# RL7005_IP_SVD register map
Vendor: Realtek
Registers are 32-bit, read-write, reset 0x0 unless marked. A register's access mark holds for its fields unless they carry their own. Offsets are from the block's base; [hi:lo] are bit positions.

## RTC_REG
Base 0x4080AA00
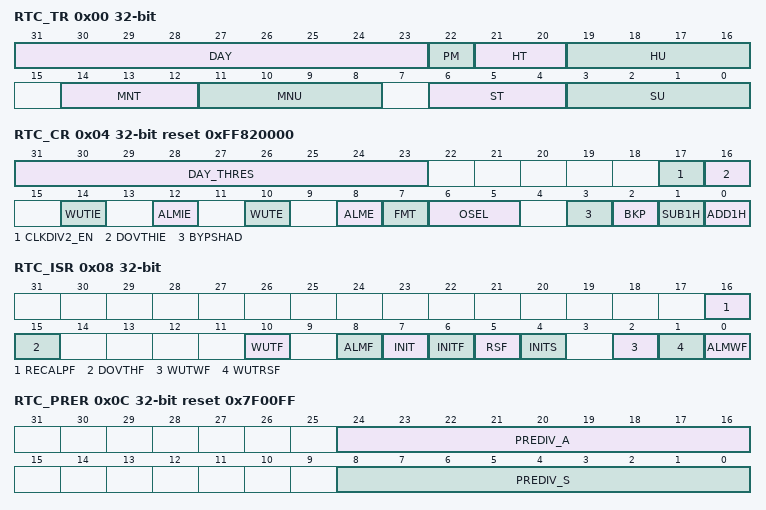
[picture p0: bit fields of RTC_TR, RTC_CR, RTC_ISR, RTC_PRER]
0x00 RTC_TR — RTC Time Reg
  [31:23] DAY — DAY in binary format
  [22] PM — PM:AM/PM notation *0: AM or 24-hour foramt *1: PM
  [21:20] HT — Hour tens in BCD format
  [19:16] HU — Hour units in BCD format
  [14:12] MNT — Minute tens in BCD format
  [11:8] MNU — Minute units in BCD format
  [6:4] ST — Second tens in BCD format
  [3:0] SU — Second units in BCD format
0x04 RTC_CR access per field reset 0xFF820000 — RTC Ctrl Reg
  [31:23] DAY_THRES ro — Day threshold in binary format
  [17] CLKDIV2_EN rw — rtc_clk/rtc_bclk use divided clock enable *0: unuse div2 clk *1: use div2 clk
  [16] DOVTHIE rw — Day over threshold interrupt enable *0: Day over threshold interrupt disabled *1: Day over threshold interrupt enabled
  [14] WUTIE rw — Wakeup timer interrupt enable *0: Wakeup timer interrupt disabled *1: Wakeup timer interrupt enabled
  [12] ALMIE rw — Alarm interrupt enable *0: Alarm interrupt disabled *1: Alarm interrupt enabled
  [10] WUTE rw — Wakeup timer enable *0: Wakeup timer disabled *1: Wakeup timer enabled
  [8] ALME rw — Alarm enable *0: Alarm disabled *1: Alarm enabled
  [7] FMT rw — Hour format *0: 24 hour/day format *1: AM/PM hour format
  [6:5] OSEL rw — Output selection.There bits are used to select the flag to be routed to RTC_OUT output. *00: Output disabled *01: Alarm output enabled *10: Clock output is clk_spre (default:1Hz) *11: Clock output is clk_apre (default:256Hz)
  [3] BYPSHAD rw — Bypass the shadow registers. *0: Calendar values (when reading from RTC_TR) are taken from the shadow register, which are updated once every two RTCCLK cycles. *1: Calendar values (when reading from RTC_TR) are taken directly from the calendar counters.
  [2] BKP rw — Backup This bit can be written by the user to memorize whether the daylight saving time change has been performed or not.
  [1] SUB1H wo — Subtract one hour(winter time change),when this bit is set outside initialization mode,1 hour is subtracted to the calendar time if the current hour is not 0,this bit is always read as 0. *0:No effect *1:subtract one hour to the current time
  [0] ADD1H wo — Add one hour(summer time change),when this bit is set outside initialization mode,1 hour is add to the calendar time,this bit is always read as 0. *0:No effect *1:add one hour to the current time
0x08 RTC_ISR access per field — RTC Init And Status Reg
  [16] RECALPF ro — Recalibration pending flag The RECALPF status flag is automatically set to '1' when software writes to the RTC_CALIBR register, indicating that the RTCCALIBR register is blocked. When the new calibration settings are taken into account, this bit returns to '0'. Refer to Re-calibration on-the-fly.
  [15] DOVTHF ro — Day over threshold flag This flag is set by hardware when the Day in RTC_TR over the DAY_THRES set in RTC_CR register.
  [10] WUTF ro — Wakeup timer flag This flag is set by hardware when the wakeup auto-reload counter reaches to. This flag must be cleared by software at least 2 RTCCLK periods before WUTF is set to '1' again.
  [8] ALMF ro — Alarm flag This flag is set by hardware when the time register (RTC_TR) matches the Alarm registers (RTC_ALMR1L and RTC_ALMR1H).
  [7] INIT rw — Initialization mode *0: Free running mode. *1: Initialization mode used to program time and date register (RTC_TR), and prescaler register (RTC_PRER). Counters are stoped and start counting from the new value when INIT is set.
  [6] INITF ro — Initialization flag. When this bit is set to '1', the RTC is in initialization state, and the time, date, and prescaler registers can be updated. *0: Calendar registers update is not allowed. *1: Calendar registers update is allowed.
  [5] RSF ro — Registers synchronization flag. This bit is set by hardware each time the calendar registers are copied into the shadow registers (RTC_TR). This bit is cleared by hardware in initialization mode or when in bypass shadow register mode (BYPSHAD=1). This bit can also be cleared by software. It is cleared either by software or by hardware in initialization mode. *0: Calendar shadow registers are not yet synchronized. *1: Calendar shadow registers are synchronized.
  [4] INITS ro — This bit is set by hardware when the calendar day field is different from 0 (RTC domain reset state). *0: Calendar has not been initialized. *1: Calendar has been initialized.
  [2] WUTWF ro — Wakeup timer write flag This flag is set by hardware when WUT value can be changed, after the WUTE bit has been set to '0' in RTC_CR. *0: Wakeup timer configuration update not allowd except in initialization mode *1: Wakeup timer configuration update allowed
  [1] WUTRSF ro — This bit is set by hardware each time the WUTE bit is copied into the shadow register. This bit is cleared by hardware in initialization mode. This bit can also be cleared by software. It is cleared either by software or by hardware in initialization mode. *0: WUTE is not yet synchronized. *1: WUTE is synchronized.
  [0] ALMWF ro — Alarm write flag This bit is set by hardware when Alarm values can be changed, after the ALME bit has been set to '0' in RTC_CR. It is cleared by hardware when ALME bit has been set to '1' in RTC_CR. *0: Alarm update not allowed *1: Alarm update allowed
0x0C RTC_PRER reset 0x7F00FF — RTC Prescaler Reg
  [24:16] PREDIV_A — Asynchronous prescaler factor This is the asynchronous division factor: clk_apre freq = RTCCLK freq/(PREDIV_A + 1)
  [8:0] PREDIV_S — Synchronous prescaler factor This is the synchronous division factor: clk_spre freq = clk_apre freq/(PREDIV_S + 1)
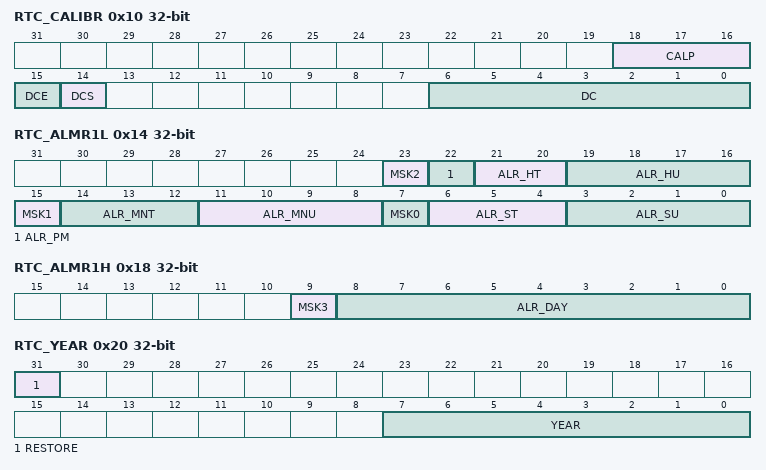
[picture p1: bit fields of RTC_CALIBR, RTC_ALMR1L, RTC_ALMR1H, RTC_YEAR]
0x10 RTC_CALIBR — RTC Calibration Reg
  [18:16] CALP — Calibration period
  [15] DCE — Digital calibration enable *0: Digital calibration disabled *1: Digital calibration enabled
  [14] DCS — Digital calibration signal *0: Positive calibration, time update frequency is increased. *1: Negative calibration, time update frequency is decreased.
  [6:0] DC — Digital calibration
0x14 RTC_ALMR1L — RTC Alarm 1 Reg Low
  [23] MSK2 — Alarm hour mask *0: Alarm set if the hours match *1: Hours don't care in Alarm comparison
  [22] ALR_PM — AM/PM notation. *0: AM or 24-hour format *1: PM
  [21:20] ALR_HT — Hour tens in BCD format
  [19:16] ALR_HU — Hour units in BCD format
  [15] MSK1 — Alarm minutes mask. *0: Alarm set if the minutes match *1: Minutes don't care in Alarm comprison
  [14:12] ALR_MNT — Minute tens in BCD format
  [11:8] ALR_MNU — Minute units in BCD format
  [7] MSK0 — Alarm seconds mask *0: Alarm set if the seconds match *1: Seconds don't care in Alarm comprison
  [6:4] ALR_ST — Second tens in BCD format
  [3:0] ALR_SU — Second units in BCD format
0x18 RTC_ALMR1H — - RTC Alarm 1 Reg High
  [9] MSK3 — Alarm day mask *0: Alarm set if the days match *1: Days don't care in Alarm comprison
  [8:0] ALR_DAY — DAY in binary format
0x1C RTC_WPR — RTC Write Protect Reg
  [7:0] KEY — Write protection key This byte is written by software. Refer to RTC register write protection for a description of how to unlock RTC register write protection.RTC write protection register,write "0xCA"then write "0x53" disable write protect,write "0xFF" enable write protect
0x20 RTC_YEAR — RTC Year Reg
  [31] RESTORE — Reset Flag. Indicates whether any reset conditions have occurred (except POR/PDR/BOD), so that the bit is set to '1' before reset, and then the global variable that determines whether the recovery time information is needed depending on whether the bit is '1'.
  [7:0] YEAR — Year in binary format
0x24 RTC_WUTR — RTC Wakeup Timer Reg
  [16:0] WUT — Wakeup auto-reload value bits When the wakeup timer is enabled (WUTE is set to '1'), the WUTF flag is set every (WUT[16:0]+1) cycles. The first assertion of WUTF occurs between WUT and (WUT+1) cycles after WUTE is set.
0x28 REG_RTC_DUMMY reset 0xFFFF — RTC Dummy Register
